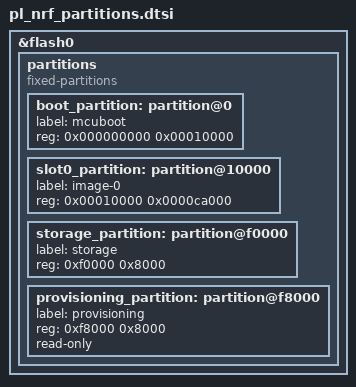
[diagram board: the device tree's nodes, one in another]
&flash0 {
  /delete-node/ partitions;
  partitions {
    compatible = "fixed-partitions";
    #address-cells = <1>;
    #size-cells = <1>;

    boot_partition: partition@0 {
      label = "mcuboot";
      reg = <0x000000000 0x00010000>;
    };
    slot0_partition: partition@10000 {
      label = "image-0";
      reg = <0x00010000 0x0000ca000>;
    };

    storage_partition: partition@f0000 {
      label = "storage";
      reg = <0xf0000 0x8000>;
    };

    provisioning_partition: partition@f8000 {
      label = "provisioning";
      reg = <0xf8000 0x8000>;
      read-only;
    };
  };
};
